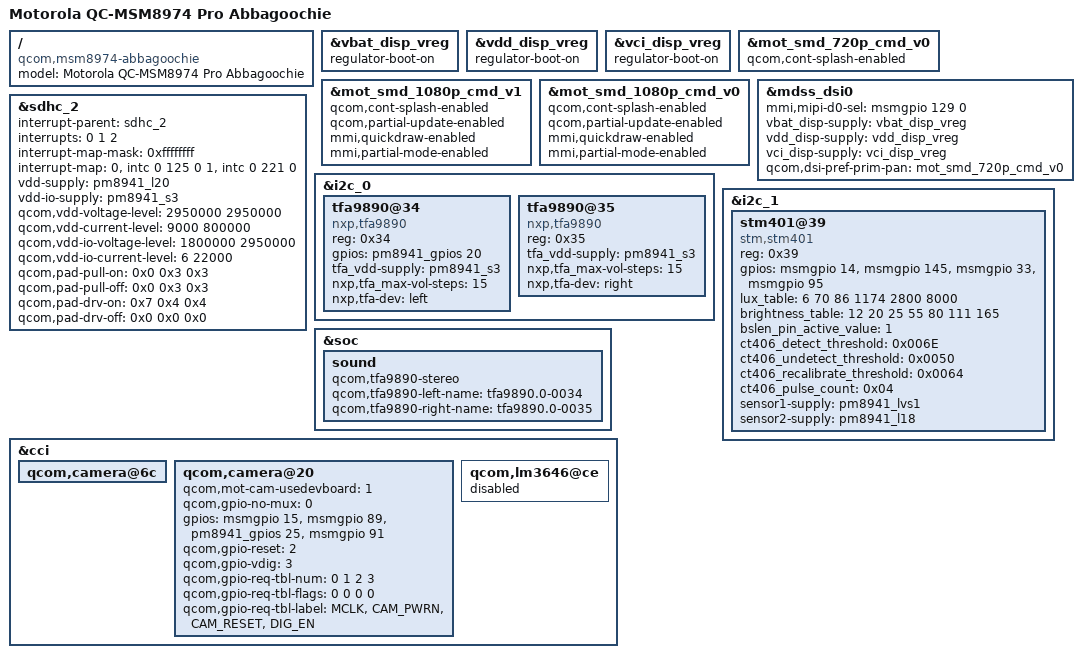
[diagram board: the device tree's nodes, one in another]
/* Copyright (c) 2013 Motorola Mobility LLC
 *
 * This program is free software; you can redistribute it and/or modify
 * it under the terms of the GNU General Public License version 2 and
 * only version 2 as published by the Free Software Foundation.
 *
 * This program is distributed in the hope that it will be useful,
 * but WITHOUT ANY WARRANTY; without even the implied warranty of
 * MERCHANTABILITY or FITNESS FOR A PARTICULAR PURPOSE.  See the
 * GNU General Public License for more details.
 */

/include/ "dsi-panel-mot-smd-720p-cmd.dtsi"
/include/ "dsi-panel-mot-smd-720p-video.dtsi"
/include/ "dsi-panel-mot-smd-1080p-cmd.dtsi"

/ {
	model = "Motorola QC-MSM8974 Pro Abbagoochie";
	compatible = "qcom,msm8974-abbagoochie",
		     "qcom,msm8974-moto",
		     "qcom,msm8974";
};

&vbat_disp_vreg {
       regulator-boot-on;
};

&vdd_disp_vreg {
       regulator-boot-on;
};

&vci_disp_vreg {
       regulator-boot-on;
};

&mot_smd_720p_cmd_v0 {
	qcom,cont-splash-enabled;
};

&mot_smd_1080p_cmd_v1 {
	qcom,cont-splash-enabled;
	qcom,partial-update-enabled;
	mmi,quickdraw-enabled;
	mmi,partial-mode-enabled;
};

&mot_smd_1080p_cmd_v0 {
	qcom,cont-splash-enabled;
	qcom,partial-update-enabled;
	mmi,quickdraw-enabled;
	mmi,partial-mode-enabled;
};

&mdss_dsi0 {
	mmi,mipi-d0-sel = <&msmgpio 129 0>;
	vbat_disp-supply = <&vbat_disp_vreg>;
	vdd_disp-supply = <&vdd_disp_vreg>;
	vci_disp-supply = <&vci_disp_vreg>;
	qcom,dsi-pref-prim-pan = <&mot_smd_720p_cmd_v0>;
};

&sdhc_2 {
	#address-cells = <0>;
	interrupt-parent = <&sdhc_2>;
	interrupts = <0 1 2>;
	#interrupt-cells = <1>;
	interrupt-map-mask = <0xffffffff>;
	interrupt-map = <0 &intc 0 125 0
			1 &intc 0 221 0>;
	interrupt-names = "hc_irq", "pwr_irq", "status_irq";

	vdd-supply = <&pm8941_l20>;
	vdd-io-supply = <&pm8941_s3>;

	qcom,vdd-voltage-level = <2950000 2950000>;
	qcom,vdd-current-level = <9000 800000>;

	qcom,vdd-io-voltage-level = <1800000 2950000>;
	qcom,vdd-io-current-level = <6 22000>;

	qcom,pad-pull-on = <0x0 0x3 0x3>; /* no-pull, pull-up, pull-up */
	qcom,pad-pull-off = <0x0 0x3 0x3>; /* no-pull, pull-up, pull-up */
	qcom,pad-drv-on = <0x7 0x4 0x4>; /* 16mA, 10mA, 10mA */
	qcom,pad-drv-off = <0x0 0x0 0x0>; /* 2mA, 2mA, 2mA */
	status = "ok";
};

&i2c_0 {
	tfa9890@34 {
		compatible = "nxp,tfa9890";
		reg = <0x34>;
		gpios = <&pm8941_gpios 20 0>;     /* RESET */
		tfa_vdd-supply = <&pm8941_s3>;
		nxp,tfa_max-vol-steps = <15>;
		nxp,tfa-dev = "left";
	};

	tfa9890@35 {
		compatible = "nxp,tfa9890";
		reg = <0x35>;
		tfa_vdd-supply = <&pm8941_s3>;
		nxp,tfa_max-vol-steps = <15>;
		nxp,tfa-dev = "right";
	};
};

&i2c_1 {
	status = "ok";

	stm401@39 {
		compatible = "stm,stm401";
		reg = <0x39>;
		gpios = <&msmgpio 14 0>,        /* IRQ */
			<&msmgpio 145 0>,       /* RESET */
			<&msmgpio 33 0>,        /* BSLEN */
			<&msmgpio 95 0>;        /* WakeIRQ */
		lux_table = <6 70 86 1174 2800 8000>;
		brightness_table = <12 20 25 55 80 111 165>;
		bslen_pin_active_value = <1>;
		ct406_detect_threshold = <0x006E>;
		ct406_undetect_threshold = <0x0050>;
		ct406_recalibrate_threshold = <0x0064>;
		ct406_pulse_count = <0x04>;
		sensor1-supply = <&pm8941_lvs1>;
		sensor2-supply = <&pm8941_l18>;
	};
};

&soc {
	sound {
		qcom,tfa9890-stereo;
		qcom,tfa9890-left-name = "tfa9890.0-0034";
		qcom,tfa9890-right-name = "tfa9890.0-0035";
	};
};

&cci {
	qcom,camera@6c {
		/delete-property/ qcom,led-flash-src;
	};

	qcom,camera@20 {
		/delete-property/ qcom,led-flash-src;
		/* This is to use SEMCO Header board with off
		 * the shelf 13MP */
		qcom,mot-cam-usedevboard = <1>;
		qcom,gpio-no-mux = <0>;
		gpios = <&msmgpio 15 0>,
			<&msmgpio 89 0>,
			<&pm8941_gpios 25 0>,
			<&msmgpio 91 0>;
		qcom,gpio-reset = <2>;
		qcom,gpio-vdig = <3>;
		qcom,gpio-req-tbl-num = <0 1 2 3>;
		qcom,gpio-req-tbl-flags = <0 0 0 0>;
		qcom,gpio-req-tbl-label = "MCLK",
					  "CAM_PWRN",
					  "CAM_RESET",
					  "DIG_EN";
	};

	qcom,lm3646@ce {
		status = "disabled";
	};
};
